VERSION "f33"

NS_ :

BS_:

BU_: LOG

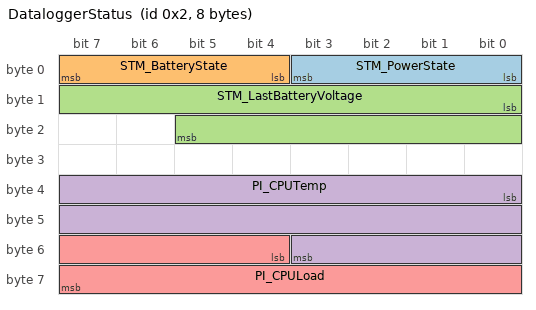
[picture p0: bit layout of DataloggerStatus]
BO_ 2 DataloggerStatus: 8 LOG
 SG_ STM_PowerState : 0|4@1+ (1,0) [0|6] "" Vector__XXX
 SG_ STM_BatteryState : 4|4@1+ (1,0) [0|2] "" Vector__XXX
 SG_ STM_LastBatteryVoltage : 8|14@1+ (0.001,0) [0|16.383] "V" Vector__XXX
 SG_ PI_CPUTemp : 32|20@1+ (0.001,0) [0|1048.575] "degC" Vector__XXX
 SG_ PI_CPULoad : 52|12@1+ (1,0) [0|4095] "%" Vector__XXX

CM_ BU_ LOG "Datalogger";
VAL_ 2 STM_PowerState 0 "OFF" 1 "SELFTEST" 2 "BOOTING" 3 "RUNNING" 4 "BACKUP" 5 "SHUTDOWN" 6 "POWEROFF";
VAL_ 2 STM_BatteryState 0 "UNKNOWN" 1 "FAILED" 2 "PASSED";
